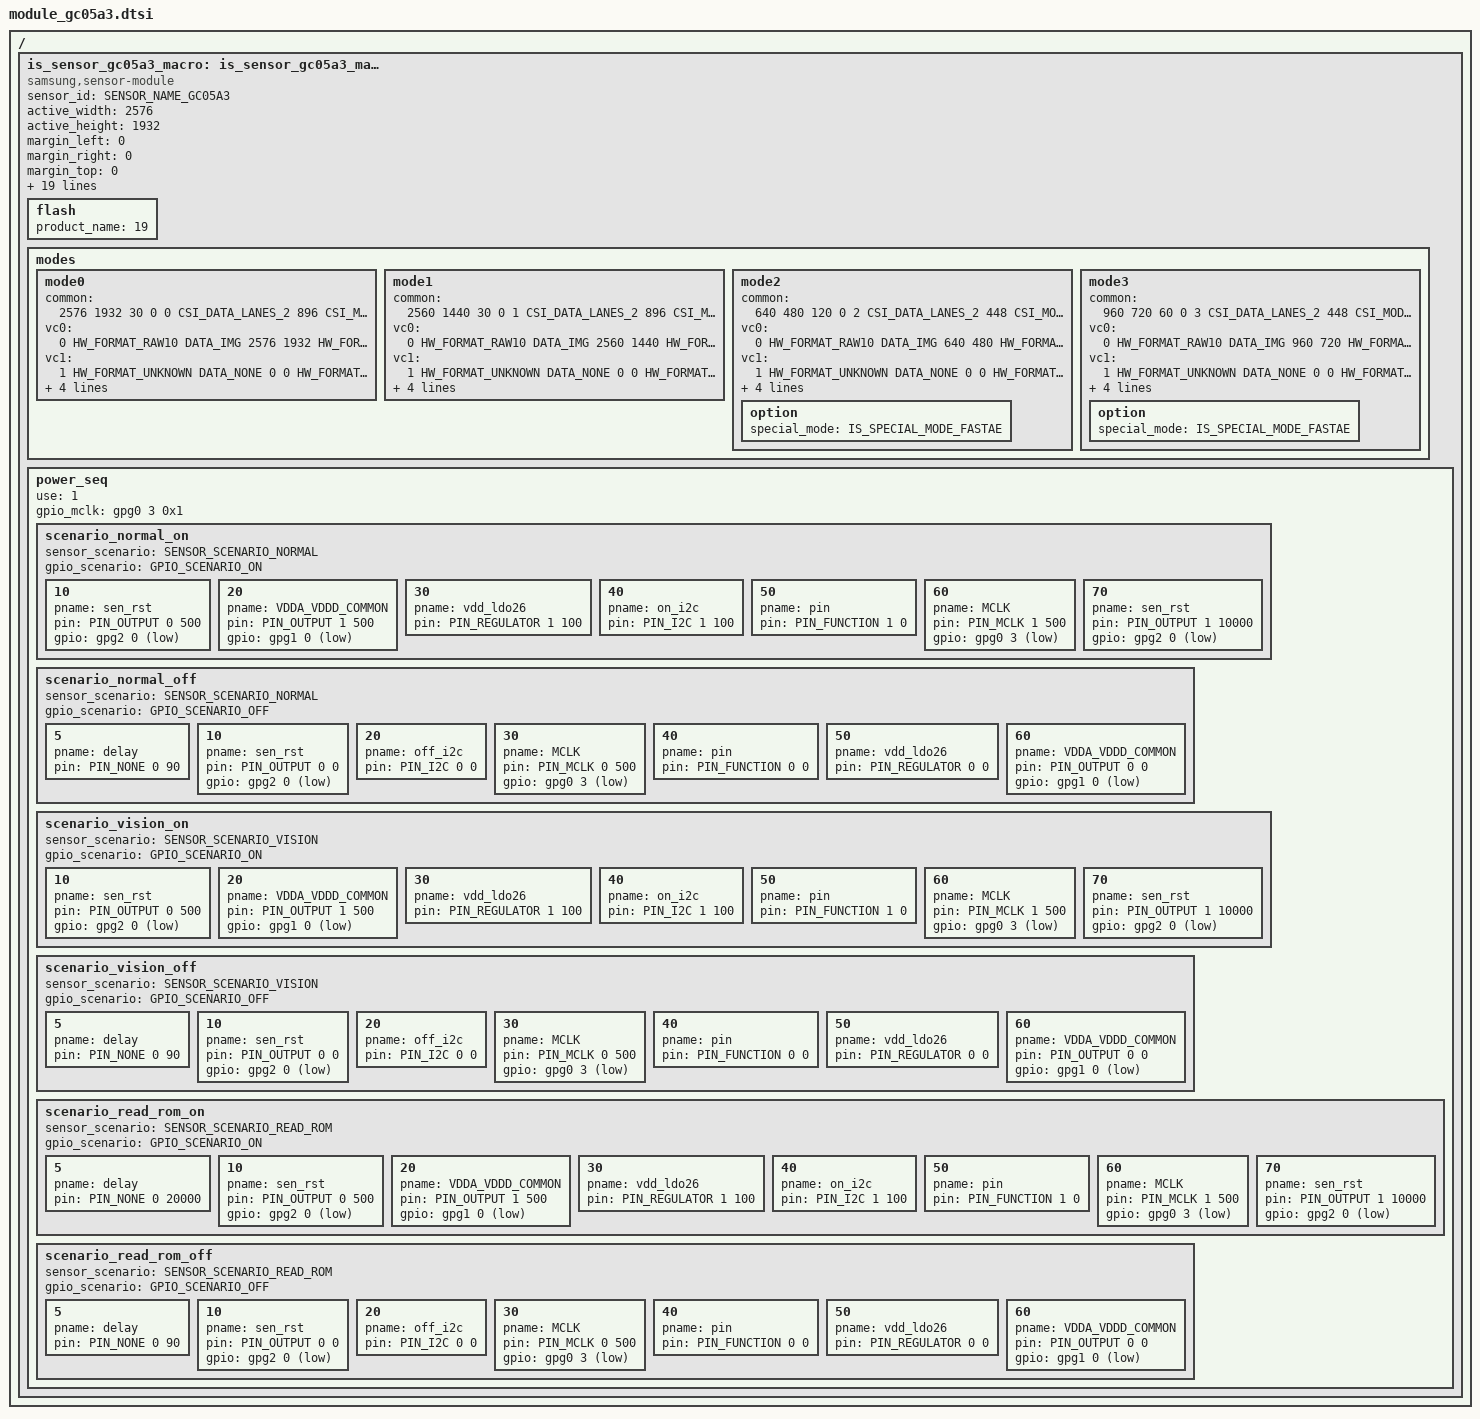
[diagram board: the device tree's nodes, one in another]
/*
 * SAMSUNG EXYNOSxxxx board camera device tree source
 *
 * Copyright (c) 2024 Samsung Electronics Co., Ltd.
 *		http://www.samsung.com
 *
 * This program is free software; you can redistribute it and/or modify
 * it under the terms of the GNU General Public License version 2 as
 * published by the Free Software Foundation.
 */

#include <dt-bindings/camera/exynos_is_dt.h>

/ {
	fragment@camera {
		target-path = "/";
		__overlay__ {
			is_sensor_gc05a3_macro: is_sensor_gc05a3_macro@7E {
				compatible = "samsung,sensor-module";

				/* common */
				sensor_id = <SENSOR_NAME_GC05A3>;
				active_width = <2576>;
				active_height = <1932>;
				margin_left = <0>;
				margin_right = <0>;
				margin_top = <0>;
				margin_bottom = <0>;
				max_framerate = <120>;
				bitwidth = <10>;
				use_retention_mode = <SENSOR_RETENTION_UNSUPPORTED>;
				sensor_maker = "GALAXYCORE";
				sensor_name = "GC05A3";
				setfile_name = "setfile_gc05a3.bin";
				pinning_setfile;

				status = "okay";

				pinctrl-names = "pin0", "pin1", "release";
				pinctrl-0 = <&sensor_mclk2_out>;
				pinctrl-1 = <&sensor_mclk2_fn>;
				pinctrl-2 = <>;

				position = <6>; /* sensor position of camera dt */
				id = <3>; /* is_sensor id */
				mclk_ch = <2>;
				mclk_freq = <19200>;
				sensor_i2c_ch = <3>; /* SENSOR_CONTROL_I2C3 lock */

				/* vendor */
				rom_id = <4>;
				rom_cal_index = <0>;

				/* peri */
				flash {
					product_name = <19>; /* S2MF301*/
				};

				/* sensor modes */
				modes {
					/* common = <width, height, fps, settle, mode, lane, speed, interleave, lrte, pd_mode> */
					/* vcX = <map, hwformat, width, height, hwformat, type, width, height> */
					/* 0 : 2576x1932 30fps */
					mode0 {
						common = <2576 1932 30 0 0 CSI_DATA_LANES_2 896 CSI_MODE_VC_DT LRTE_DISABLE PD_NONE EX_NONE>;
						vc0 = </* in */ 0 HW_FORMAT_RAW10 DATA_IMG 2576 1932	/* out */ HW_FORMAT_RAW10 VC_NOTHING 2576 1932>;
						vc1 = </* in */ 1 HW_FORMAT_UNKNOWN DATA_NONE 0 0		/* out */ HW_FORMAT_UNKNOWN VC_NOTHING 0 0>;
						vc2 = </* in */ 2 HW_FORMAT_UNKNOWN DATA_NONE 0 0		/* out */ HW_FORMAT_UNKNOWN VC_NOTHING 0 0>;
						vc3 = </* in */ 3 HW_FORMAT_UNKNOWN DATA_NONE 0 0		/* out */ HW_FORMAT_UNKNOWN VC_NOTHING 0 0>;
					};
					/* 1 : 2560x1440 30fps */
					mode1 {
						common = <2560 1440 30 0 1 CSI_DATA_LANES_2 896 CSI_MODE_VC_DT LRTE_DISABLE PD_NONE EX_NONE>;
						vc0 = </* in */ 0 HW_FORMAT_RAW10 DATA_IMG 2560 1440	/* out */ HW_FORMAT_RAW10 VC_NOTHING 2560 1440>;
						vc1 = </* in */ 1 HW_FORMAT_UNKNOWN DATA_NONE 0 0		/* out */ HW_FORMAT_UNKNOWN VC_NOTHING 0 0>;
						vc2 = </* in */ 2 HW_FORMAT_UNKNOWN DATA_NONE 0 0		/* out */ HW_FORMAT_UNKNOWN VC_NOTHING 0 0>;
						vc3 = </* in */ 3 HW_FORMAT_UNKNOWN DATA_NONE 0 0		/* out */ HW_FORMAT_UNKNOWN VC_NOTHING 0 0>;
					};
					/* 2 : 640x480 2Binning 120fps */
					mode2 {
						common = <640 480 120 0 2 CSI_DATA_LANES_2 448 CSI_MODE_VC_DT LRTE_DISABLE PD_NONE EX_NONE>;
						vc0 = </* in */ 0 HW_FORMAT_RAW10 DATA_IMG 640 480		/* out */ HW_FORMAT_RAW10 VC_NOTHING 640 480>;
						vc1 = </* in */ 1 HW_FORMAT_UNKNOWN DATA_NONE 0 0		/* out */ HW_FORMAT_UNKNOWN VC_NOTHING 0 0>;
						vc2 = </* in */ 2 HW_FORMAT_UNKNOWN DATA_NONE 0 0		/* out */ HW_FORMAT_UNKNOWN VC_NOTHING 0 0>;
						vc3 = </* in */ 3 HW_FORMAT_UNKNOWN DATA_NONE 0 0		/* out */ HW_FORMAT_UNKNOWN VC_NOTHING 0 0>;
						option { special_mode = <IS_SPECIAL_MODE_FASTAE>; };
					};
					/* 3 : 960x720 2Binning 60fps */
					mode3 {
						common = <960 720 60 0 3 CSI_DATA_LANES_2 448 CSI_MODE_VC_DT LRTE_DISABLE PD_NONE EX_NONE>;
						vc0 = </* in */ 0 HW_FORMAT_RAW10 DATA_IMG 960 720		/* out */ HW_FORMAT_RAW10 VC_NOTHING 960 720>;
						vc1 = </* in */ 1 HW_FORMAT_UNKNOWN DATA_NONE 0 0		/* out */ HW_FORMAT_UNKNOWN VC_NOTHING 0 0>;
						vc2 = </* in */ 2 HW_FORMAT_UNKNOWN DATA_NONE 0 0		/* out */ HW_FORMAT_UNKNOWN VC_NOTHING 0 0>;
						vc3 = </* in */ 3 HW_FORMAT_UNKNOWN DATA_NONE 0 0		/* out */ HW_FORMAT_UNKNOWN VC_NOTHING 0 0>;
						option { special_mode = <IS_SPECIAL_MODE_FASTAE>; };
					};
				};

				power_seq {
					use = <1>;
					gpio_mclk = <&gpg0 3 0x1>;
					scenario_normal_on {
						sensor_scenario = <SENSOR_SCENARIO_NORMAL>;
						gpio_scenario = <GPIO_SCENARIO_ON>;

						/* A start node number should be over the 10 for reserved number 0~9. */
						/* pname = "name"; pin = <act value delay voltage>; gpio = <gpx# # 0x1>; */
						10 { pname = "sen_rst"; pin = <PIN_OUTPUT 0 500>; gpio = <&gpg2 0 0x1>; };
						20 { pname = "VDDA_VDDD_COMMON"; pin = <PIN_OUTPUT 1 500>; gpio = <&gpg1 0 0x1>; };
						30 { pname = "vdd_ldo26"; pin = <PIN_REGULATOR 1 100>; }; /* VDDIO_COMMON_1P8 */
						40 { pname = "on_i2c"; pin = <PIN_I2C 1 100>; };
						50 { pname = "pin"; pin = <PIN_FUNCTION 1 0>; };
						60 { pname = "MCLK"; pin = <PIN_MCLK 1 500>; gpio = <&gpg0 3 0x1>; };
						70 { pname = "sen_rst"; pin = <PIN_OUTPUT 1 10000>; gpio = <&gpg2 0 0x1>; };
					};

					scenario_normal_off {
						sensor_scenario = <SENSOR_SCENARIO_NORMAL>;
						gpio_scenario = <GPIO_SCENARIO_OFF>;
						/* A start node number should be over the 10 for reserved number 0~9. */
						/* pname = "name"; pin = <act value delay voltage>; gpio = <gpx# # 0x1>; */
						5 { pname = "delay"; pin = <PIN_NONE 0 90>; };
						10 { pname = "sen_rst"; pin = <PIN_OUTPUT 0 0>; gpio = <&gpg2 0 0x1>; };
						20 { pname = "off_i2c"; pin = <PIN_I2C 0 0>; };
						30 { pname = "MCLK"; pin = <PIN_MCLK 0 500>; gpio = <&gpg0 3 0x1>; };
						40 { pname = "pin"; pin = <PIN_FUNCTION 0 0>; };
						50 { pname = "vdd_ldo26"; pin = <PIN_REGULATOR 0 0>; };
						60 { pname = "VDDA_VDDD_COMMON"; pin = <PIN_OUTPUT 0 0>; gpio = <&gpg1 0 0x1>; };
					};

					scenario_vision_on {
						sensor_scenario = <SENSOR_SCENARIO_VISION>;
						gpio_scenario = <GPIO_SCENARIO_ON>;

						/* A start node number should be over the 10 for reserved number 0~9. */
						/* pname = "name"; pin = <act value delay voltage>; gpio = <gpx# # 0x1>; */
						10 { pname = "sen_rst"; pin = <PIN_OUTPUT 0 500>; gpio = <&gpg2 0 0x1>; };
						20 { pname = "VDDA_VDDD_COMMON"; pin = <PIN_OUTPUT 1 500>; gpio = <&gpg1 0 0x1>; };
						30 { pname = "vdd_ldo26"; pin = <PIN_REGULATOR 1 100>; }; /* VDDIO_COMMON_1P8 */
						40 { pname = "on_i2c"; pin = <PIN_I2C 1 100>; };
						50 { pname = "pin"; pin = <PIN_FUNCTION 1 0>; };
						60 { pname = "MCLK"; pin = <PIN_MCLK 1 500>; gpio = <&gpg0 3 0x1>; };
						70 { pname = "sen_rst"; pin = <PIN_OUTPUT 1 10000>; gpio = <&gpg2 0 0x1>; };
					};

					scenario_vision_off {
						sensor_scenario = <SENSOR_SCENARIO_VISION>;
						gpio_scenario = <GPIO_SCENARIO_OFF>;

						/* A start node number should be over the 10 for reserved number 0~9. */
						/* pname = "name"; pin = <act value delay voltage>; gpio = <gpx# # 0x1>; */
						5 { pname = "delay"; pin = <PIN_NONE 0 90>; };
						10 { pname = "sen_rst"; pin = <PIN_OUTPUT 0 0>; gpio = <&gpg2 0 0x1>; };
						20 { pname = "off_i2c"; pin = <PIN_I2C 0 0>; };
						30 { pname = "MCLK"; pin = <PIN_MCLK 0 500>; gpio = <&gpg0 3 0x1>; };
						40 { pname = "pin"; pin = <PIN_FUNCTION 0 0>; };
						50 { pname = "vdd_ldo26"; pin = <PIN_REGULATOR 0 0>; };
						60 { pname = "VDDA_VDDD_COMMON"; pin = <PIN_OUTPUT 0 0>; gpio = <&gpg1 0 0x1>; };
					};

					scenario_read_rom_on {
						sensor_scenario = <SENSOR_SCENARIO_READ_ROM>;
						gpio_scenario = <GPIO_SCENARIO_ON>;
						/* pname = "name"; pin = <act value delay voltage>; gpio = <gpx# # 0x1>; */
						5 { pname = "delay"; pin = <PIN_NONE 0 20000>; };
						10 { pname = "sen_rst"; pin = <PIN_OUTPUT 0 500>; gpio = <&gpg2 0 0x1>; };
						20 { pname = "VDDA_VDDD_COMMON"; pin = <PIN_OUTPUT 1 500>; gpio = <&gpg1 0 0x1>; };
						30 { pname = "vdd_ldo26"; pin = <PIN_REGULATOR 1 100>; }; /* VDDIO_COMMON_1P8 */
						40 { pname = "on_i2c"; pin = <PIN_I2C 1 100>; };
						50 { pname = "pin"; pin = <PIN_FUNCTION 1 0>; };
						60 { pname = "MCLK"; pin = <PIN_MCLK 1 500>; gpio = <&gpg0 3 0x1>; };
						70 { pname = "sen_rst"; pin = <PIN_OUTPUT 1 10000>; gpio = <&gpg2 0 0x1>; };
					};

					scenario_read_rom_off {
						sensor_scenario = <SENSOR_SCENARIO_READ_ROM>;
						gpio_scenario = <GPIO_SCENARIO_OFF>;
						/* pname = "name"; pin = <act value delay voltage>; gpio = <gpx# # 0x1>; */
						5 { pname = "delay"; pin = <PIN_NONE 0 90>; };
						10 { pname = "sen_rst"; pin = <PIN_OUTPUT 0 0>; gpio = <&gpg2 0 0x1>; };
						20 { pname = "off_i2c"; pin = <PIN_I2C 0 0>; };
						30 { pname = "MCLK"; pin = <PIN_MCLK 0 500>; gpio = <&gpg0 3 0x1>; };
						40 { pname = "pin"; pin = <PIN_FUNCTION 0 0>; };
						50 { pname = "vdd_ldo26"; pin = <PIN_REGULATOR 0 0>; };
						60 { pname = "VDDA_VDDD_COMMON"; pin = <PIN_OUTPUT 0 0>; gpio = <&gpg1 0 0x1>; };
					};
				};
			};
		}; /* end of __overlay__ */
	}; /* end of fragment */
}; /* end of root */
